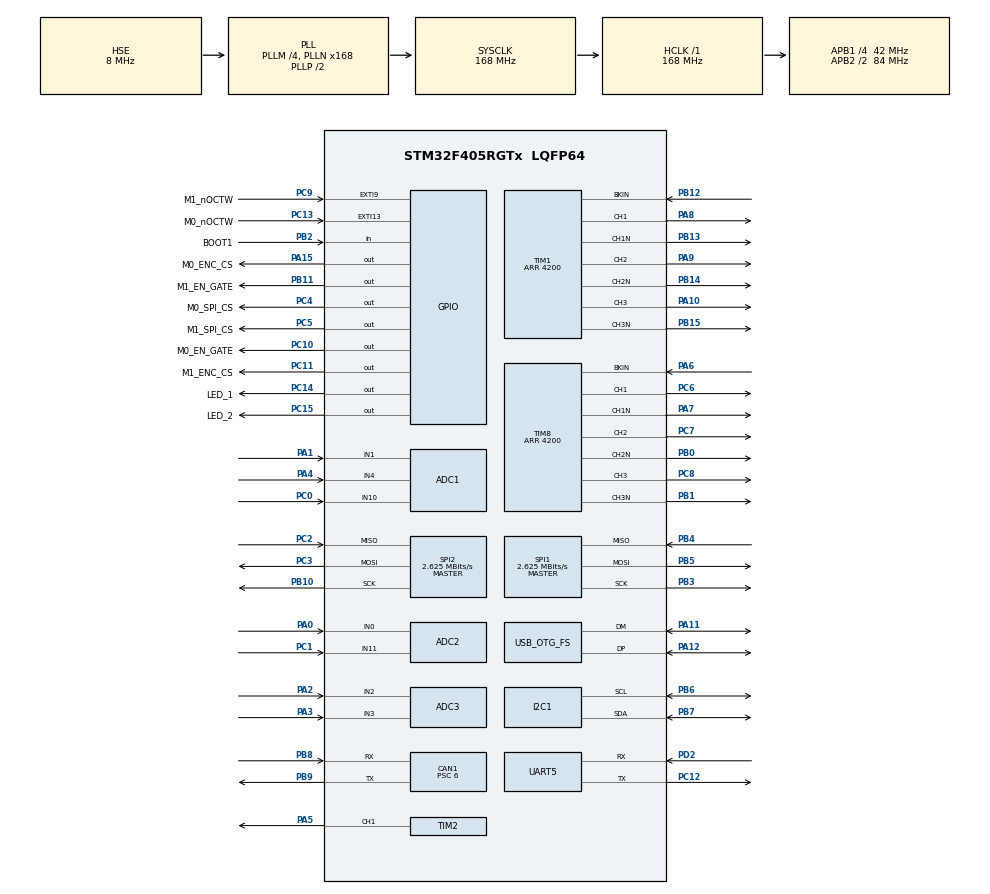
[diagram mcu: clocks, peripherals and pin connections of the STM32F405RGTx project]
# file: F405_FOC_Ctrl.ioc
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ADC1.Channel-0\#ChannelRegularConversion=ADC_CHANNEL_4
ADC1.Channel-1\#ChannelInjectedConversion=ADC_CHANNEL_10
ADC1.Channel-2\#ChannelInjectedConversion=ADC_CHANNEL_1
ADC1.ExternalTrigInjecConv=ADC_EXTERNALTRIGINJECCONV_T1_TRGO
ADC1.InjNumberOfConversion=2
ADC1.InjectedOffset-1\#ChannelInjectedConversion=0
ADC1.InjectedOffset-2\#ChannelInjectedConversion=0
ADC1.InjectedRank-1\#ChannelInjectedConversion=1
ADC1.InjectedRank-2\#ChannelInjectedConversion=2
ADC1.Mode=ADC_DUALMODE_INJECSIMULT
ADC1.NbrOfConversionFlag=1
ADC1.Rank-0\#ChannelRegularConversion=1
ADC1.SamplingTime-0\#ChannelRegularConversion=ADC_SAMPLETIME_144CYCLES
ADC1.SamplingTime-1\#ChannelInjectedConversion=ADC_SAMPLETIME_28CYCLES
ADC1.SamplingTime-2\#ChannelInjectedConversion=ADC_SAMPLETIME_28CYCLES
ADC1.ScanConvMode=ENABLE
ADC1.master=1
ADC2.Channel-0\#ChannelRegularConversion=ADC_CHANNEL_0
ADC2.Channel-2\#ChannelInjectedConversion=ADC_CHANNEL_11
ADC2.Channel-3\#ChannelInjectedConversion=ADC_CHANNEL_0
ADC2.InjNumberOfConversion=2
ADC2.InjectedOffset-2\#ChannelInjectedConversion=0
ADC2.InjectedOffset-3\#ChannelInjectedConversion=0
ADC2.InjectedRank-2\#ChannelInjectedConversion=1
ADC2.InjectedRank-3\#ChannelInjectedConversion=2
ADC2.Mode=ADC_DUALMODE_INJECSIMULT
ADC2.NbrOfConversion=1
ADC2.NbrOfConversionFlag=1
ADC2.Rank-0\#ChannelRegularConversion=1
ADC2.SamplingTime-0\#ChannelRegularConversion=ADC_SAMPLETIME_3CYCLES
ADC2.SamplingTime-2\#ChannelInjectedConversion=ADC_SAMPLETIME_28CYCLES
ADC2.SamplingTime-3\#ChannelInjectedConversion=ADC_SAMPLETIME_28CYCLES
ADC3.Channel-0\#ChannelRegularConversion=ADC_CHANNEL_2
ADC3.Channel-1\#ChannelRegularConversion=ADC_CHANNEL_3
ADC3.Mode=ADC_DUALMODE_INJECSIMULT
ADC3.NbrOfConversion=2
ADC3.NbrOfConversionFlag=1
ADC3.Rank-0\#ChannelRegularConversion=1
ADC3.Rank-1\#ChannelRegularConversion=2
ADC3.SamplingTime-0\#ChannelRegularConversion=ADC_SAMPLETIME_144CYCLES
ADC3.SamplingTime-1\#ChannelRegularConversion=ADC_SAMPLETIME_144CYCLES
ADC3.ScanConvMode=ENABLE
CAN1.ABOM=ENABLE
CAN1.BS1=CAN_BS1_11TQ
CAN1.BS2=CAN_BS2_2TQ
CAN1.CalculateBaudRate=500000
CAN1.CalculateTimeBit=2000
CAN1.CalculateTimeQuantum=142.85714285714286
CAN1.NART=ENABLE
CAN1.Prescaler=6
Dma.ADC1.0.Direction=DMA_PERIPH_TO_MEMORY
Dma.ADC1.0.FIFOMode=DMA_FIFOMODE_DISABLE
Dma.ADC1.0.Instance=DMA2_Stream0
Dma.ADC1.0.MemDataAlignment=DMA_MDATAALIGN_HALFWORD
Dma.ADC1.0.MemInc=DMA_MINC_ENABLE
Dma.ADC1.0.Mode=DMA_NORMAL
Dma.ADC1.0.PeriphDataAlignment=DMA_PDATAALIGN_HALFWORD
Dma.ADC1.0.PeriphInc=DMA_PINC_DISABLE
Dma.ADC1.0.Priority=DMA_PRIORITY_LOW
Dma.ADC3.1.Direction=DMA_PERIPH_TO_MEMORY
Dma.ADC3.1.FIFOMode=DMA_FIFOMODE_DISABLE
Dma.ADC3.1.Instance=DMA2_Stream1
Dma.ADC3.1.MemDataAlignment=DMA_MDATAALIGN_HALFWORD
Dma.ADC3.1.MemInc=DMA_MINC_ENABLE
Dma.ADC3.1.Mode=DMA_NORMAL
Dma.ADC3.1.PeriphDataAlignment=DMA_PDATAALIGN_HALFWORD
Dma.ADC3.1.PeriphInc=DMA_PINC_DISABLE
Dma.ADC3.1.Priority=DMA_PRIORITY_LOW
Dma.I2C1_RX.4.Direction=DMA_PERIPH_TO_MEMORY
Dma.I2C1_RX.4.FIFOMode=DMA_FIFOMODE_DISABLE
Dma.I2C1_RX.4.Instance=DMA1_Stream5
Dma.I2C1_RX.4.MemDataAlignment=DMA_MDATAALIGN_BYTE
Dma.I2C1_RX.4.MemInc=DMA_MINC_ENABLE
Dma.I2C1_RX.4.Mode=DMA_NORMAL
Dma.I2C1_RX.4.PeriphDataAlignment=DMA_PDATAALIGN_BYTE
Dma.I2C1_RX.4.PeriphInc=DMA_PINC_DISABLE
Dma.I2C1_RX.4.Priority=DMA_PRIORITY_LOW
Dma.I2C1_TX.5.Direction=DMA_MEMORY_TO_PERIPH
Dma.I2C1_TX.5.FIFOMode=DMA_FIFOMODE_DISABLE
Dma.I2C1_TX.5.Instance=DMA1_Stream6
Dma.I2C1_TX.5.MemDataAlignment=DMA_MDATAALIGN_BYTE
Dma.I2C1_TX.5.MemInc=DMA_MINC_ENABLE
Dma.I2C1_TX.5.Mode=DMA_NORMAL
Dma.I2C1_TX.5.PeriphDataAlignment=DMA_PDATAALIGN_BYTE
Dma.I2C1_TX.5.PeriphInc=DMA_PINC_DISABLE
Dma.I2C1_TX.5.Priority=DMA_PRIORITY_LOW
Dma.Request0=ADC1
Dma.Request1=ADC3
Dma.Request2=SPI2_RX
Dma.Request3=SPI2_TX
Dma.Request4=I2C1_RX
Dma.Request5=I2C1_TX
Dma.Request6=UART5_RX
Dma.Request7=UART5_TX
Dma.Request8=SPI1_RX
Dma.Request9=SPI1_TX
Dma.SPI1_RX.8.Direction=DMA_PERIPH_TO_MEMORY
Dma.SPI1_RX.8.FIFOMode=DMA_FIFOMODE_DISABLE
Dma.SPI1_RX.8.Instance=DMA2_Stream2
Dma.SPI1_RX.8.MemDataAlignment=DMA_MDATAALIGN_BYTE
Dma.SPI1_RX.8.MemInc=DMA_MINC_ENABLE
Dma.SPI1_RX.8.Mode=DMA_NORMAL
Dma.SPI1_RX.8.PeriphDataAlignment=DMA_PDATAALIGN_BYTE
Dma.SPI1_RX.8.PeriphInc=DMA_PINC_DISABLE
Dma.SPI1_RX.8.Priority=DMA_PRIORITY_LOW
Dma.SPI1_TX.9.Direction=DMA_MEMORY_TO_PERIPH
Dma.SPI1_TX.9.FIFOMode=DMA_FIFOMODE_DISABLE
Dma.SPI1_TX.9.Instance=DMA2_Stream3
Dma.SPI1_TX.9.MemDataAlignment=DMA_MDATAALIGN_BYTE
Dma.SPI1_TX.9.MemInc=DMA_MINC_ENABLE
Dma.SPI1_TX.9.Mode=DMA_NORMAL
Dma.SPI1_TX.9.PeriphDataAlignment=DMA_PDATAALIGN_BYTE
Dma.SPI1_TX.9.PeriphInc=DMA_PINC_DISABLE
Dma.SPI1_TX.9.Priority=DMA_PRIORITY_LOW
Dma.SPI2_RX.2.Direction=DMA_PERIPH_TO_MEMORY
Dma.SPI2_RX.2.FIFOMode=DMA_FIFOMODE_DISABLE
Dma.SPI2_RX.2.Instance=DMA1_Stream3
Dma.SPI2_RX.2.MemDataAlignment=DMA_MDATAALIGN_HALFWORD
Dma.SPI2_RX.2.MemInc=DMA_MINC_ENABLE
Dma.SPI2_RX.2.Mode=DMA_NORMAL
Dma.SPI2_RX.2.PeriphDataAlignment=DMA_PDATAALIGN_HALFWORD
Dma.SPI2_RX.2.PeriphInc=DMA_PINC_DISABLE
Dma.SPI2_RX.2.Priority=DMA_PRIORITY_LOW
Dma.SPI2_TX.3.Direction=DMA_MEMORY_TO_PERIPH
Dma.SPI2_TX.3.FIFOMode=DMA_FIFOMODE_DISABLE
Dma.SPI2_TX.3.Instance=DMA1_Stream4
Dma.SPI2_TX.3.MemDataAlignment=DMA_MDATAALIGN_HALFWORD
Dma.SPI2_TX.3.MemInc=DMA_MINC_ENABLE
Dma.SPI2_TX.3.Mode=DMA_NORMAL
Dma.SPI2_TX.3.PeriphDataAlignment=DMA_PDATAALIGN_HALFWORD
Dma.SPI2_TX.3.PeriphInc=DMA_PINC_DISABLE
Dma.SPI2_TX.3.Priority=DMA_PRIORITY_LOW
Dma.UART5_RX.6.Direction=DMA_PERIPH_TO_MEMORY
Dma.UART5_RX.6.FIFOMode=DMA_FIFOMODE_DISABLE
Dma.UART5_RX.6.Instance=DMA1_Stream0
Dma.UART5_RX.6.MemDataAlignment=DMA_MDATAALIGN_BYTE
Dma.UART5_RX.6.MemInc=DMA_MINC_ENABLE
Dma.UART5_RX.6.Mode=DMA_CIRCULAR
Dma.UART5_RX.6.PeriphDataAlignment=DMA_PDATAALIGN_BYTE
Dma.UART5_RX.6.PeriphInc=DMA_PINC_DISABLE
Dma.UART5_RX.6.Priority=DMA_PRIORITY_LOW
Dma.UART5_TX.7.Direction=DMA_MEMORY_TO_PERIPH
Dma.UART5_TX.7.FIFOMode=DMA_FIFOMODE_DISABLE
Dma.UART5_TX.7.Instance=DMA1_Stream7
Dma.UART5_TX.7.MemDataAlignment=DMA_MDATAALIGN_BYTE
Dma.UART5_TX.7.MemInc=DMA_MINC_ENABLE
Dma.UART5_TX.7.Mode=DMA_NORMAL
Dma.UART5_TX.7.PeriphDataAlignment=DMA_PDATAALIGN_BYTE
Dma.UART5_TX.7.PeriphInc=DMA_PINC_DISABLE
Dma.UART5_TX.7.Priority=DMA_PRIORITY_LOW
Mcu.Family=STM32F4
Mcu.Name=STM32F405RGTx
Mcu.Package=LQFP64
NVIC.ADC_IRQn=true\:1\:0\:true\:false\:true\:true\:true\:true
NVIC.CAN1_RX0_IRQn=true\:5\:0\:true\:false\:true\:true\:true\:true
NVIC.CAN1_SCE_IRQn=true\:5\:0\:true\:false\:true\:true\:true\:true
NVIC.DMA1_Stream0_IRQn=true\:4\:0\:true\:false\:true\:false\:true\:true
NVIC.DMA1_Stream3_IRQn=true\:5\:0\:true\:false\:true\:false\:true\:true
NVIC.DMA1_Stream4_IRQn=true\:5\:0\:true\:false\:true\:false\:true\:true
NVIC.DMA1_Stream5_IRQn=true\:6\:0\:true\:false\:true\:false\:true\:true
NVIC.DMA1_Stream6_IRQn=true\:6\:0\:true\:false\:true\:false\:true\:true
NVIC.DMA1_Stream7_IRQn=true\:4\:0\:true\:false\:true\:false\:true\:true
NVIC.DMA2_Stream0_IRQn=true\:6\:0\:true\:false\:true\:false\:true\:true
NVIC.DMA2_Stream1_IRQn=true\:6\:0\:true\:false\:true\:false\:true\:true
NVIC.DMA2_Stream2_IRQn=true\:2\:0\:true\:false\:true\:false\:true\:true
NVIC.DMA2_Stream3_IRQn=true\:2\:0\:true\:false\:true\:false\:true\:true
NVIC.EXTI15_10_IRQn=true\:6\:0\:true\:false\:true\:true\:true\:true
NVIC.EXTI9_5_IRQn=true\:6\:0\:true\:false\:true\:true\:true\:true
NVIC.I2C1_ER_IRQn=true\:6\:0\:true\:false\:true\:true\:true\:true
NVIC.I2C1_EV_IRQn=true\:6\:0\:true\:false\:true\:true\:true\:true
NVIC.OTG_FS_IRQn=true\:6\:0\:true\:false\:true\:false\:true\:true
NVIC.PriorityGroup=NVIC_PRIORITYGROUP_4
NVIC.SPI1_IRQn=true\:2\:0\:true\:false\:true\:true\:true\:true
NVIC.SPI2_IRQn=true\:5\:0\:true\:false\:true\:true\:true\:true
NVIC.TIM1_BRK_TIM9_IRQn=true\:0\:0\:false\:false\:true\:true\:true\:true
NVIC.TIM8_BRK_TIM12_IRQn=true\:0\:0\:false\:false\:true\:true\:true\:true
NVIC.UART5_IRQn=true\:4\:0\:true\:false\:true\:true\:true\:true
PA0-WKUP.Signal=ADCx_IN0
PA1.Signal=ADCx_IN1
PA10.GPIO_Speed=GPIO_SPEED_FREQ_HIGH
PA10.Signal=S_TIM1_CH3
PA11.Mode=Device_Only
PA11.Signal=USB_OTG_FS_DM
PA12.Mode=Device_Only
PA12.Signal=USB_OTG_FS_DP
PA13.Mode=Serial_Wire
PA13.Signal=SYS_JTMS-SWDIO
PA14.Mode=Serial_Wire
PA14.Signal=SYS_JTCK-SWCLK
PA15.GPIO_Label=M0_ENC_CS
PA15.PinState=GPIO_PIN_SET
PA15.Signal=GPIO_Output
PA2.Signal=ADCx_IN2
PA3.Signal=ADCx_IN3
PA4.Signal=ADCx_IN4
PA5.GPIO_Speed=GPIO_SPEED_FREQ_HIGH
PA5.Signal=S_TIM2_CH1_ETR
PA6.Mode=Activate-Break-Input
PA6.Signal=TIM8_BKIN
PA7.GPIO_Speed=GPIO_SPEED_FREQ_HIGH
PA7.Mode=PWM Generation1 CH1 CH1N
PA7.Signal=TIM8_CH1N
PA8.GPIO_Speed=GPIO_SPEED_FREQ_HIGH
PA8.Signal=S_TIM1_CH1
PA9.GPIO_Speed=GPIO_SPEED_FREQ_HIGH
PA9.Signal=S_TIM1_CH2
PB0.GPIO_Speed=GPIO_SPEED_FREQ_HIGH
PB0.Mode=PWM Generation2 CH2 CH2N
PB0.Signal=TIM8_CH2N
PB1.GPIO_Speed=GPIO_SPEED_FREQ_HIGH
PB1.Mode=PWM Generation3 CH3 CH3N
PB1.Signal=TIM8_CH3N
PB10.Mode=Full_Duplex_Master
PB10.Signal=SPI2_SCK
PB11.GPIO_Label=M1_EN_GATE
PB11.Signal=GPIO_Output
PB12.Mode=Activate-Break-Input
PB12.Signal=TIM1_BKIN
PB13.GPIO_Speed=GPIO_SPEED_FREQ_HIGH
PB13.Mode=PWM Generation1 CH1 CH1N
PB13.Signal=TIM1_CH1N
PB14.GPIO_Speed=GPIO_SPEED_FREQ_HIGH
PB14.Mode=PWM Generation2 CH2 CH2N
PB14.Signal=TIM1_CH2N
PB15.GPIO_Speed=GPIO_SPEED_FREQ_HIGH
PB15.Mode=PWM Generation3 CH3 CH3N
PB15.Signal=TIM1_CH3N
PB2.GPIO_Label=BOOT1
PB2.Signal=GPIO_Input
PB3.Mode=Full_Duplex_Master
PB3.Signal=SPI1_SCK
PB4.Mode=Full_Duplex_Master
PB4.Signal=SPI1_MISO
PB5.Mode=Full_Duplex_Master
PB5.Signal=SPI1_MOSI
PB6.GPIO_Speed=GPIO_SPEED_FREQ_HIGH
PB6.Mode=I2C
PB6.Signal=I2C1_SCL
PB7.GPIO_Speed=GPIO_SPEED_FREQ_HIGH
PB7.Mode=I2C
PB7.Signal=I2C1_SDA
PB8.Mode=CAN_Activate
PB8.Signal=CAN1_RX
PB9.Mode=CAN_Activate
PB9.Signal=CAN1_TX
PC0.Signal=ADCx_IN10
PC1.Signal=ADCx_IN11
PC10.GPIO_Label=M0_EN_GATE
PC10.Signal=GPIO_Output
PC11.GPIO_Label=M1_ENC_CS
PC11.PinState=GPIO_PIN_SET
PC11.Signal=GPIO_Output
PC12.GPIO_Speed=GPIO_SPEED_FREQ_HIGH
PC12.Mode=Asynchronous
PC12.Signal=UART5_TX
PC13-ANTI_TAMP.GPIO_Label=M0_nOCTW
PC13-ANTI_TAMP.GPIO_ModeDefaultEXTI=GPIO_MODE_IT_FALLING
PC13-ANTI_TAMP.Signal=GPXTI13
PC14-OSC32_IN.GPIO_Label=LED_1
PC14-OSC32_IN.PinState=GPIO_PIN_SET
PC14-OSC32_IN.Signal=GPIO_Output
PC15-OSC32_OUT.GPIO_Label=LED_2
PC15-OSC32_OUT.PinState=GPIO_PIN_SET
PC15-OSC32_OUT.Signal=GPIO_Output
PC2.Mode=Full_Duplex_Master
PC2.Signal=SPI2_MISO
PC3.Mode=Full_Duplex_Master
PC3.Signal=SPI2_MOSI
PC4.GPIO_Label=M0_SPI_CS
PC4.PinState=GPIO_PIN_SET
PC4.Signal=GPIO_Output
PC5.GPIO_Label=M1_SPI_CS
PC5.PinState=GPIO_PIN_SET
PC5.Signal=GPIO_Output
PC6.GPIO_Speed=GPIO_SPEED_FREQ_HIGH
PC6.Signal=S_TIM8_CH1
PC7.GPIO_Speed=GPIO_SPEED_FREQ_HIGH
PC7.Signal=S_TIM8_CH2
PC8.GPIO_Speed=GPIO_SPEED_FREQ_HIGH
PC8.Signal=S_TIM8_CH3
PC9.GPIO_Label=M1_nOCTW
PC9.GPIO_ModeDefaultEXTI=GPIO_MODE_IT_FALLING
PC9.Signal=GPXTI9
PD2.GPIO_Speed=GPIO_SPEED_FREQ_HIGH
PD2.Mode=Asynchronous
PD2.Signal=UART5_RX
PH0-OSC_IN.Mode=HSE-External-Oscillator
PH0-OSC_IN.Signal=RCC_OSC_IN
PH1-OSC_OUT.Mode=HSE-External-Oscillator
PH1-OSC_OUT.Signal=RCC_OSC_OUT
ProjectManager.HeapSize=0x200
ProjectManager.StackSize=0x1000
ProjectManager.TargetToolchain=MDK-ARM V5.32
RCC.48MHZClocksFreq_Value=48000000
RCC.AHBFreq_Value=168000000
RCC.APB1CLKDivider=RCC_HCLK_DIV4
RCC.APB1Freq_Value=42000000
RCC.APB1TimFreq_Value=84000000
RCC.APB2CLKDivider=RCC_HCLK_DIV2
RCC.APB2Freq_Value=84000000
RCC.APB2TimFreq_Value=168000000
RCC.CortexFreq_Value=168000000
RCC.HCLKFreq_Value=168000000
RCC.HSE_VALUE=8000000
RCC.HSI_VALUE=16000000
RCC.LSE_VALUE=32768
RCC.PLLM=4
RCC.PLLN=168
RCC.PLLQ=7
RCC.SYSCLKFreq_VALUE=168000000
RCC.SYSCLKSource=RCC_SYSCLKSOURCE_PLLCLK
RCC.VCOOutputFreq_Value=336000000
SH.ADCx_IN0.0=ADC2_IN0,IN0
SH.ADCx_IN1.0=ADC1_IN1,IN1
SH.ADCx_IN10.0=ADC1_IN10,IN10
SH.ADCx_IN11.0=ADC2_IN11,IN11
SH.ADCx_IN2.0=ADC3_IN2,IN2
SH.ADCx_IN3.0=ADC3_IN3,IN3
SH.ADCx_IN4.0=ADC1_IN4,IN4
SH.S_TIM1_CH1.0=TIM1_CH1,PWM Generation1 CH1 CH1N
SH.S_TIM1_CH2.0=TIM1_CH2,PWM Generation2 CH2 CH2N
SH.S_TIM1_CH3.0=TIM1_CH3,PWM Generation3 CH3 CH3N
SH.S_TIM2_CH1_ETR.0=TIM2_CH1,PWM Generation1 CH1
SH.S_TIM8_CH1.0=TIM8_CH1,PWM Generation1 CH1 CH1N
SH.S_TIM8_CH2.0=TIM8_CH2,PWM Generation2 CH2 CH2N
SH.S_TIM8_CH3.0=TIM8_CH3,PWM Generation3 CH3 CH3N
SPI1.BaudRatePrescaler=SPI_BAUDRATEPRESCALER_32
SPI1.CLKPhase=SPI_PHASE_2EDGE
SPI1.CLKPolarity=SPI_POLARITY_HIGH
SPI1.CalculateBaudRate=2.625 MBits/s
SPI1.Direction=SPI_DIRECTION_2LINES
SPI1.Mode=SPI_MODE_MASTER
SPI1.VirtualType=VM_MASTER
SPI2.BaudRatePrescaler=SPI_BAUDRATEPRESCALER_16
SPI2.CLKPhase=SPI_PHASE_2EDGE
SPI2.CalculateBaudRate=2.625 MBits/s
SPI2.DataSize=SPI_DATASIZE_16BIT
SPI2.Direction=SPI_DIRECTION_2LINES
SPI2.Mode=SPI_MODE_MASTER
SPI2.VirtualType=VM_MASTER
TIM1.AutoReloadPreload=TIM_AUTORELOAD_PRELOAD_ENABLE
TIM1.AutomaticOutput=TIM_AUTOMATICOUTPUT_DISABLE
TIM1.BreakPolarity=TIM_BREAKPOLARITY_LOW
TIM1.Channel-PWM\ Generation1\ CH1\ CH1N=TIM_CHANNEL_1
TIM1.Channel-PWM\ Generation2\ CH2\ CH2N=TIM_CHANNEL_2
TIM1.Channel-PWM\ Generation3\ CH3\ CH3N=TIM_CHANNEL_3
TIM1.Channel-PWM\ Generation4\ No\ Output=TIM_CHANNEL_4
TIM1.CounterMode=TIM_COUNTERMODE_CENTERALIGNED1
TIM1.DeadTime=80
TIM1.OCMode_PWM-PWM\ Generation1\ CH1\ CH1N=TIM_OCMODE_PWM2
TIM1.OCMode_PWM-PWM\ Generation2\ CH2\ CH2N=TIM_OCMODE_PWM2
TIM1.OCMode_PWM-PWM\ Generation3\ CH3\ CH3N=TIM_OCMODE_PWM2
TIM1.OCMode_PWM-PWM\ Generation4\ No\ Output=TIM_OCMODE_PWM2
TIM1.OffStateIDLEMode=TIM_OSSI_ENABLE
TIM1.OffStateRunMode=TIM_OSSR_ENABLE
TIM1.Period=4200
TIM1.Pulse-PWM\ Generation1\ CH1\ CH1N=2100
TIM1.Pulse-PWM\ Generation2\ CH2\ CH2N=2100
TIM1.Pulse-PWM\ Generation3\ CH3\ CH3N=2100
TIM1.Pulse-PWM\ Generation4\ No\ Output=3864
TIM1.RepetitionCounter=1
TIM1.TIM_MasterOutputTrigger=TIM_TRGO_OC4REF
TIM2.AutoReloadPreload=TIM_AUTORELOAD_PRELOAD_ENABLE
TIM2.Channel-PWM\ Generation1\ CH1=TIM_CHANNEL_1
TIM2.Period=999
TIM2.Prescaler=83
TIM8.AutoReloadPreload=TIM_AUTORELOAD_PRELOAD_ENABLE
TIM8.BreakPolarity=TIM_BREAKPOLARITY_LOW
TIM8.Channel-PWM\ Generation1\ CH1\ CH1N=TIM_CHANNEL_1
TIM8.Channel-PWM\ Generation2\ CH2\ CH2N=TIM_CHANNEL_2
TIM8.Channel-PWM\ Generation3\ CH3\ CH3N=TIM_CHANNEL_3
TIM8.CounterMode=TIM_COUNTERMODE_CENTERALIGNED1
TIM8.DeadTime=96
TIM8.OCMode_PWM-PWM\ Generation1\ CH1\ CH1N=TIM_OCMODE_PWM2
TIM8.OCMode_PWM-PWM\ Generation2\ CH2\ CH2N=TIM_OCMODE_PWM2
TIM8.OCMode_PWM-PWM\ Generation3\ CH3\ CH3N=TIM_OCMODE_PWM2
TIM8.OffStateIDLEMode=TIM_OSSI_ENABLE
TIM8.OffStateRunMode=TIM_OSSR_ENABLE
TIM8.Period=4200
TIM8.Pulse-PWM\ Generation1\ CH1\ CH1N=2100
TIM8.Pulse-PWM\ Generation2\ CH2\ CH2N=2100
TIM8.Pulse-PWM\ Generation3\ CH3\ CH3N=2100
TIM8.RepetitionCounter=1
UART5.VirtualMode=Asynchronous
USB_DEVICE.CLASS_NAME_FS=CDC
USB_DEVICE.VirtualMode-CDC_FS=Cdc
USB_DEVICE.VirtualModeFS=Cdc_FS
USB_OTG_FS.VirtualMode=Device_Only
VP_TIM1_VS_ClockSourceINT.Mode=Internal
VP_TIM1_VS_no_output4.Mode=PWM Generation4 No Output
VP_TIM2_VS_ClockSourceINT.Mode=Internal
VP_TIM8_VS_ClockSourceINT.Mode=Internal
VP_TIM8_VS_ClockSourceITR.Mode=TriggerSource_ITR0
VP_TIM8_VS_ControllerModeTrigger.Mode=Trigger Mode
VP_USB_DEVICE_VS_USB_DEVICE_CDC_FS.Mode=CDC_FS
board=custom

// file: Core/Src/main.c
/* USER CODE BEGIN Header */
/**
  ******************************************************************************
  * @file           : main.c
  * @brief          : Main program body
  ******************************************************************************
  * @attention
  *
  * Copyright (c) 2026 STMicroelectronics.
  * All rights reserved.
  *
  * This software is licensed under terms that can be found in the LICENSE file
  * in the root directory of this software component.
  * If no LICENSE file comes with this software, it is provided AS-IS.
  *
  ******************************************************************************
  */
/* USER CODE END Header */
#include "main.h"
#include "adc.h"
#include "can.h"
#include "dma.h"
#include "i2c.h"
#include "spi.h"
#include "tim.h"
#include "usart.h"
#include "usb_device.h"
#include "gpio.h"

/* USER CODE BEGIN Includes */
#include "app.h"

/* USER CODE END Includes */

void SystemClock_Config(void);

int main(void)
{

  /* MCU Configuration--------------------------------------------------------*/

  /* Reset of all peripherals, Initializes the Flash interface and the Systick. */
  HAL_Init();

  /* Configure the system clock */
  SystemClock_Config();

  /* Initialize all configured peripherals */
  MX_GPIO_Init();
  MX_DMA_Init();
  MX_TIM1_Init();
  MX_TIM8_Init();
  MX_TIM2_Init();
  MX_ADC1_Init();
  MX_ADC2_Init();
  MX_ADC3_Init();
  MX_SPI2_Init();
  MX_SPI1_Init();
  MX_I2C1_Init();
  MX_CAN1_Init();
  MX_UART5_Init();
  MX_USB_DEVICE_Init();
  /* USER CODE BEGIN 2 */
  App_Init();
  /* 从 EEPROM 恢复参数；未校准轴保持关闭，不自动校准或下发转速。 */
  /* USER CODE END 2 */

  /* Infinite loop */
  while (1)
  {

    /* USER CODE BEGIN 3 */
    App_Poll();
  }
  /* USER CODE END 3 */
}

void SystemClock_Config(void)
{
  RCC_OscInitTypeDef RCC_OscInitStruct = {0};
  RCC_ClkInitTypeDef RCC_ClkInitStruct = {0};

  /** Configure the main internal regulator output voltage
  */
  __HAL_RCC_PWR_CLK_ENABLE();
  __HAL_PWR_VOLTAGESCALING_CONFIG(PWR_REGULATOR_VOLTAGE_SCALE1);

  /** Initializes the RCC Oscillators according to the specified parameters
  * in the RCC_OscInitTypeDef structure.
  */
  RCC_OscInitStruct.OscillatorType = RCC_OSCILLATORTYPE_HSE;
  RCC_OscInitStruct.HSEState = RCC_HSE_ON;
  RCC_OscInitStruct.PLL.PLLState = RCC_PLL_ON;
  RCC_OscInitStruct.PLL.PLLSource = RCC_PLLSOURCE_HSE;
  RCC_OscInitStruct.PLL.PLLM = 4;
  RCC_OscInitStruct.PLL.PLLN = 168;
  RCC_OscInitStruct.PLL.PLLP = RCC_PLLP_DIV2;
  RCC_OscInitStruct.PLL.PLLQ = 7;
  if (HAL_RCC_OscConfig(&RCC_OscInitStruct) != HAL_OK)
  {
    Error_Handler();
  }

  /** Initializes the CPU, AHB and APB buses clocks
  */
  RCC_ClkInitStruct.ClockType = RCC_CLOCKTYPE_HCLK|RCC_CLOCKTYPE_SYSCLK
                              |RCC_CLOCKTYPE_PCLK1|RCC_CLOCKTYPE_PCLK2;
  RCC_ClkInitStruct.SYSCLKSource = RCC_SYSCLKSOURCE_PLLCLK;
  RCC_ClkInitStruct.AHBCLKDivider = RCC_SYSCLK_DIV1;
  RCC_ClkInitStruct.APB1CLKDivider = RCC_HCLK_DIV4;
  RCC_ClkInitStruct.APB2CLKDivider = RCC_HCLK_DIV2;

  if (HAL_RCC_ClockConfig(&RCC_ClkInitStruct, FLASH_LATENCY_5) != HAL_OK)
  {
    Error_Handler();
  }
}

void Error_Handler(void)
{
  __disable_irq();
  while (1)
  {
  }
}
